VERSION ""

NS_ :

BS_:

BU_: Chalmers BatteryGateWay

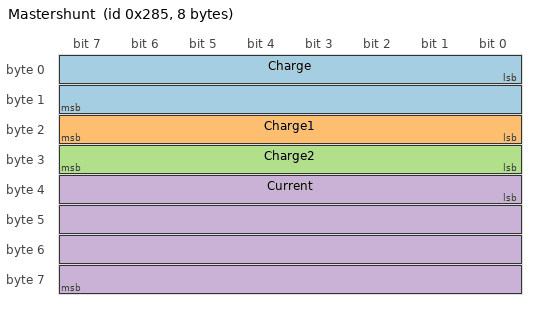
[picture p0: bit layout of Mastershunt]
BO_ 645 Mastershunt: 8 BatteryGateWay
 SG_ Charge : 0|16@1+ (1,0) [0|100] "Percent" Vector__XXX
 SG_ Charge1 : 16|8@1+ (1,0) [0|255] "V" Vector__XXX
 SG_ Charge2 : 24|8@1+ (1,0) [0|255] "V" Vector__XXX
 SG_ Current : 32|32@1+ (0.01,0) [-32|32] "A" Vector__XXX

CM_ SG_ 645 StateOfCharge "65024 - 65279 Error ; 65280 - 65535 Not available";
BA_DEF_  "Manufacturer" STRING ;
BA_DEF_  "Baudrate" INT 100000 1000000;
BA_DEF_ BO_  "GenMsgSendType" ENUM  "Cyclic","NotUsed","NotUsed","NotUsed","NotUsed","Cyclic","NotUsed","IfActive","NoMsgSendType","NotUsed";
BA_DEF_ BO_  "GenMsgCycleTime" INT 0 50000;
BA_DEF_  "BusType" STRING ;
BA_DEF_DEF_  "Manufacturer" "VolvoTrucks_CVDE";
BA_DEF_DEF_  "Baudrate" 250000;
BA_DEF_DEF_  "GenMsgSendType" "Cyclic";
BA_DEF_DEF_  "GenMsgCycleTime" 0;
BA_DEF_DEF_  "BusType" "CAN";
BA_ "GenMsgCycleTime" BO_ 262 10;
